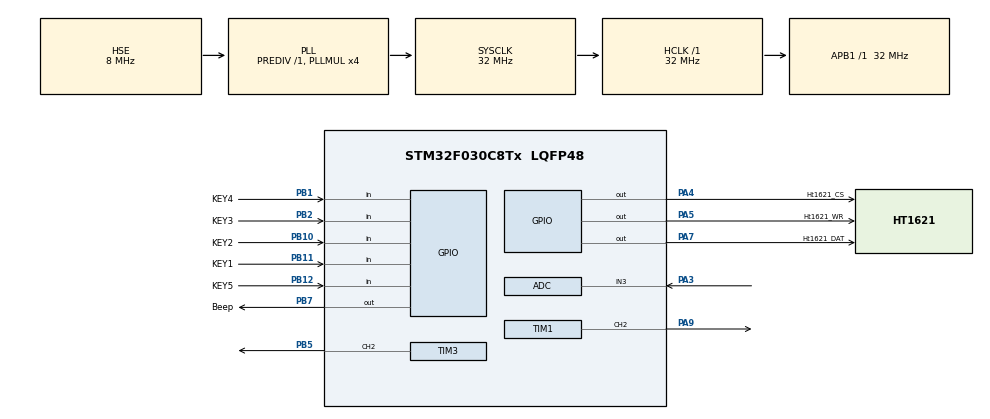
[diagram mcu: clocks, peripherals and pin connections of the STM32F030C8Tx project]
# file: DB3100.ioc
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Mcu.Family=STM32F0
Mcu.Name=STM32F030C8Tx
Mcu.Package=LQFP48
NVIC.TIM1_BRK_UP_TRG_COM_IRQn=true\:0\:0\:false\:false\:true\:true\:true
NVIC.TIM1_CC_IRQn=true\:0\:0\:false\:false\:true\:true\:true
NVIC.TIM3_IRQn=true\:0\:0\:false\:false\:true\:true\:true
PA13.Mode=Serial_Wire
PA13.Signal=SYS_SWDIO
PA14.Mode=Serial_Wire
PA14.Signal=SYS_SWCLK
PA3.Mode=IN3
PA3.Signal=ADC_IN3
PA4.GPIO_Label=Ht1621_CS
PA4.GPIO_ModeDefaultOutputPP=GPIO_MODE_OUTPUT_PP
PA4.GPIO_PuPd=GPIO_PULLUP
PA4.GPIO_Speed=GPIO_SPEED_FREQ_HIGH
PA4.PinState=GPIO_PIN_SET
PA4.Signal=GPIO_Output
PA5.GPIO_Label=Ht1621_WR
PA5.GPIO_ModeDefaultOutputPP=GPIO_MODE_OUTPUT_PP
PA5.GPIO_PuPd=GPIO_PULLUP
PA5.GPIO_Speed=GPIO_SPEED_FREQ_HIGH
PA5.PinState=GPIO_PIN_SET
PA5.Signal=GPIO_Output
PA7.GPIO_Label=Ht1621_DAT
PA7.GPIO_ModeDefaultOutputPP=GPIO_MODE_OUTPUT_PP
PA7.GPIO_PuPd=GPIO_PULLUP
PA7.GPIO_Speed=GPIO_SPEED_FREQ_HIGH
PA7.PinState=GPIO_PIN_SET
PA7.Signal=GPIO_Output
PA9.Signal=S_TIM1_CH2
PB1.GPIO_Label=KEY4
PB1.GPIO_PuPd=GPIO_PULLDOWN
PB1.Signal=GPIO_Input
PB10.GPIO_Label=KEY2
PB10.GPIO_PuPd=GPIO_PULLDOWN
PB10.Signal=GPIO_Input
PB11.GPIO_Label=KEY1
PB11.GPIO_PuPd=GPIO_PULLDOWN
PB11.Signal=GPIO_Input
PB12.GPIO_Label=KEY5
PB12.GPIO_PuPd=GPIO_PULLDOWN
PB12.Signal=GPIO_Input
PB2.GPIO_Label=KEY3
PB2.GPIO_PuPd=GPIO_PULLDOWN
PB2.Signal=GPIO_Input
PB5.Signal=S_TIM3_CH2
PB7.GPIO_Label=Beep
PB7.Signal=GPIO_Output
PF0-OSC_IN.Mode=HSE-External-Oscillator
PF0-OSC_IN.Signal=RCC_OSC_IN
PF1-OSC_OUT.Mode=HSE-External-Oscillator
PF1-OSC_OUT.Signal=RCC_OSC_OUT
ProjectManager.HeapSize=0x200
ProjectManager.StackSize=0x400
ProjectManager.TargetToolchain=MDK-ARM V5.32
RCC.AHBFreq_Value=32000000
RCC.APB1Freq_Value=32000000
RCC.APB1TimFreq_Value=32000000
RCC.HCLKFreq_Value=32000000
RCC.PLLMUL=RCC_PLL_MUL4
RCC.PLLSourceVirtual=RCC_PLLSOURCE_HSE
RCC.SYSCLKFreq_VALUE=32000000
RCC.SYSCLKSource=RCC_SYSCLKSOURCE_PLLCLK
SH.S_TIM1_CH2.0=TIM1_CH2,PWM Generation2 CH2
SH.S_TIM3_CH2.0=TIM3_CH2,PWM Generation2 CH2
TIM1.Channel-PWM\ Generation2\ CH2=TIM_CHANNEL_2
TIM1.Period=200-1
TIM1.Prescaler=8-1
TIM3.Channel-PWM\ Generation2\ CH2=TIM_CHANNEL_2
TIM3.Period=1000
TIM3.Prescaler=31
VP_TIM1_VS_ClockSourceINT.Mode=Internal
VP_TIM3_VS_ClockSourceINT.Mode=Internal
board=custom

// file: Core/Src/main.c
/* USER CODE BEGIN Header */
/**
  ******************************************************************************
  * @file           : main.c
  * @brief          : Main program body
  ******************************************************************************
  * @attention
  *
  * <h2><center>&copy; Copyright (c) 2021 STMicroelectronics.
  * All rights reserved.</center></h2>
  *
  * This software component is licensed by ST under BSD 3-Clause license,
  * the "License"; You may not use this file except in compliance with the
  * License. You may obtain a copy of the License at:
  *                        opensource.org/licenses/BSD-3-Clause
  *
  ******************************************************************************
  */
/* USER CODE END Header */
#include "main.h"
#include "adc.h"
#include "tim.h"
#include "gpio.h"

/* USER CODE BEGIN PTD */
/**********结构体************/
_sys_ sys;//系统
/* USER CODE END PTD */

void SystemClock_Config(void);

int main(void)
{
  /* USER CODE BEGIN 1 */
    /************系统初始化成功*************/
     sys.Init_ok = 0;
  /* USER CODE END 1 */

  /* MCU Configuration--------------------------------------------------------*/

  /* Reset of all peripherals, Initializes the Flash interface and the Systick. */
  HAL_Init();

  /* Configure the system clock */
  SystemClock_Config();

  /* Initialize all configured peripherals */
  MX_GPIO_Init();
  MX_TIM1_Init();
  MX_ADC_Init();
  MX_TIM3_Init();
  /* USER CODE BEGIN 2 */
    HAL_TIM_PWM_Start(&htim1, TIM_CHANNEL_2);//开启tim1通道2的pwm
    HAL_TIM_PWM_Start(&htim3, TIM_CHANNEL_2);//开启tim3通道2的pwm
    VLED = 160;//设置pwm值为160，控制背光电压
    HEAT = 0;//加热模块pwm 0—400
    lcd_init();//lcd初始话
    HAL_Delay (5);
    Sys_Init();//系统参数初始化
    /************系统初始化成功*************/
    sys.Init_ok = 1;
  /* USER CODE END 2 */

  /* Infinite loop */
  /* USER CODE BEGIN WHILE */
  while (1)
  {
    LCD_Display();//显示界面
    /* USER CODE END WHILE */

  }
}

void SystemClock_Config(void)
{
  RCC_OscInitTypeDef RCC_OscInitStruct = {0};
  RCC_ClkInitTypeDef RCC_ClkInitStruct = {0};

  /** Initializes the RCC Oscillators according to the specified parameters
  * in the RCC_OscInitTypeDef structure.
  */
  RCC_OscInitStruct.OscillatorType = RCC_OSCILLATORTYPE_HSI14|RCC_OSCILLATORTYPE_HSE;
  RCC_OscInitStruct.HSEState = RCC_HSE_ON;
  RCC_OscInitStruct.HSI14State = RCC_HSI14_ON;
  RCC_OscInitStruct.HSI14CalibrationValue = 16;
  RCC_OscInitStruct.PLL.PLLState = RCC_PLL_ON;
  RCC_OscInitStruct.PLL.PLLSource = RCC_PLLSOURCE_HSE;
  RCC_OscInitStruct.PLL.PLLMUL = RCC_PLL_MUL4;
  RCC_OscInitStruct.PLL.PREDIV = RCC_PREDIV_DIV1;
  if (HAL_RCC_OscConfig(&RCC_OscInitStruct) != HAL_OK)
  {
    Error_Handler();
  }
  /** Initializes the CPU, AHB and APB buses clocks
  */
  RCC_ClkInitStruct.ClockType = RCC_CLOCKTYPE_HCLK|RCC_CLOCKTYPE_SYSCLK
                              |RCC_CLOCKTYPE_PCLK1;
  RCC_ClkInitStruct.SYSCLKSource = RCC_SYSCLKSOURCE_PLLCLK;
  RCC_ClkInitStruct.AHBCLKDivider = RCC_SYSCLK_DIV1;
  RCC_ClkInitStruct.APB1CLKDivider = RCC_HCLK_DIV1;

  if (HAL_RCC_ClockConfig(&RCC_ClkInitStruct, FLASH_LATENCY_1) != HAL_OK)
  {
    Error_Handler();
  }
}

void Error_Handler(void)
{
  __disable_irq();
  while (1)
  {
  }
}

/************************ (C) COPYRIGHT STMicroelectronics *****END OF FILE****/
